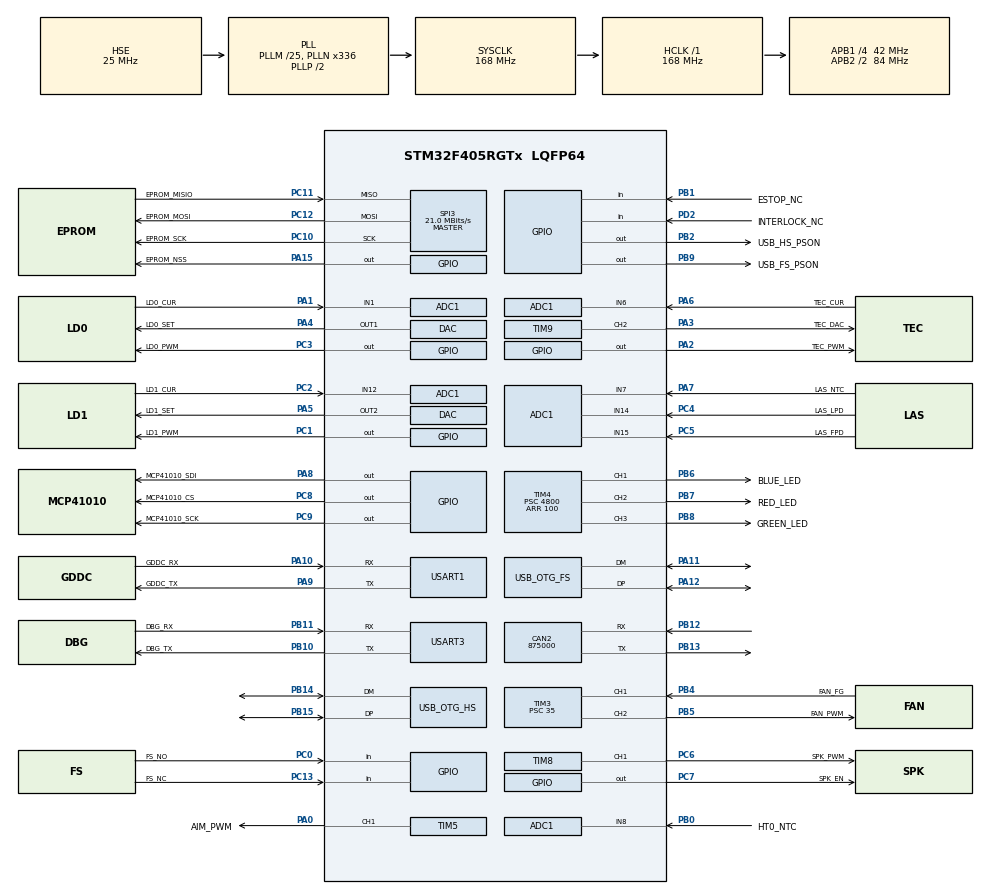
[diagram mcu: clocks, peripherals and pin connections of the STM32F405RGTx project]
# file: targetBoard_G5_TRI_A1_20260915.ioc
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ADC1.Channel-0\#ChannelRegularConversion=ADC_CHANNEL_1
ADC1.Channel-1\#ChannelRegularConversion=ADC_CHANNEL_6
ADC1.Channel-2\#ChannelRegularConversion=ADC_CHANNEL_7
ADC1.Channel-3\#ChannelRegularConversion=ADC_CHANNEL_8
ADC1.Channel-4\#ChannelRegularConversion=ADC_CHANNEL_12
ADC1.Channel-5\#ChannelRegularConversion=ADC_CHANNEL_14
ADC1.Channel-6\#ChannelRegularConversion=ADC_CHANNEL_15
ADC1.Channel-7\#ChannelRegularConversion=ADC_CHANNEL_TEMPSENSOR
ADC1.Channel-8\#ChannelRegularConversion=ADC_CHANNEL_VREFINT
ADC1.Channel-9\#ChannelRegularConversion=ADC_CHANNEL_VBAT
ADC1.ContinuousConvMode=ENABLE
ADC1.DMAContinuousRequests=ENABLE
ADC1.NbrOfConversion=10
ADC1.NbrOfConversionFlag=1
ADC1.Rank-0\#ChannelRegularConversion=1
ADC1.Rank-1\#ChannelRegularConversion=2
ADC1.Rank-2\#ChannelRegularConversion=3
ADC1.Rank-3\#ChannelRegularConversion=4
ADC1.Rank-4\#ChannelRegularConversion=5
ADC1.Rank-5\#ChannelRegularConversion=6
ADC1.Rank-6\#ChannelRegularConversion=7
ADC1.Rank-7\#ChannelRegularConversion=8
ADC1.Rank-8\#ChannelRegularConversion=9
ADC1.Rank-9\#ChannelRegularConversion=10
ADC1.SamplingTime-0\#ChannelRegularConversion=ADC_SAMPLETIME_144CYCLES
ADC1.SamplingTime-1\#ChannelRegularConversion=ADC_SAMPLETIME_144CYCLES
ADC1.SamplingTime-2\#ChannelRegularConversion=ADC_SAMPLETIME_144CYCLES
ADC1.SamplingTime-3\#ChannelRegularConversion=ADC_SAMPLETIME_144CYCLES
ADC1.SamplingTime-4\#ChannelRegularConversion=ADC_SAMPLETIME_144CYCLES
ADC1.SamplingTime-5\#ChannelRegularConversion=ADC_SAMPLETIME_144CYCLES
ADC1.SamplingTime-6\#ChannelRegularConversion=ADC_SAMPLETIME_144CYCLES
ADC1.SamplingTime-7\#ChannelRegularConversion=ADC_SAMPLETIME_144CYCLES
ADC1.SamplingTime-8\#ChannelRegularConversion=ADC_SAMPLETIME_144CYCLES
ADC1.SamplingTime-9\#ChannelRegularConversion=ADC_SAMPLETIME_144CYCLES
ADC1.ScanConvMode=ENABLE
ADC1.master=1
CAN2.CalculateBaudRate=875000
CAN2.CalculateTimeBit=1142
CAN2.CalculateTimeQuantum=380.95238095238096
Dma.ADC1.0.Direction=DMA_PERIPH_TO_MEMORY
Dma.ADC1.0.FIFOMode=DMA_FIFOMODE_ENABLE
Dma.ADC1.0.FIFOThreshold=DMA_FIFO_THRESHOLD_FULL
Dma.ADC1.0.Instance=DMA2_Stream0
Dma.ADC1.0.MemBurst=DMA_MBURST_SINGLE
Dma.ADC1.0.MemDataAlignment=DMA_MDATAALIGN_HALFWORD
Dma.ADC1.0.MemInc=DMA_MINC_ENABLE
Dma.ADC1.0.Mode=DMA_NORMAL
Dma.ADC1.0.PeriphBurst=DMA_PBURST_SINGLE
Dma.ADC1.0.PeriphDataAlignment=DMA_PDATAALIGN_HALFWORD
Dma.ADC1.0.PeriphInc=DMA_PINC_DISABLE
Dma.ADC1.0.Priority=DMA_PRIORITY_LOW
Dma.Request0=ADC1
FATFS._CODE_PAGE=437
FATFS._FS_EXFAT=1
FATFS._FS_LOCK=255
FATFS._STRF_ENCODE=0
FATFS._USE_CHMOD=1
FATFS._USE_EXPAND=1
FATFS._USE_FIND=1
FATFS._USE_FORWARD=1
FATFS._USE_LABEL=1
FATFS._USE_LFN=2
FATFS._USE_MUTEX=1
FATFS._USE_TRIM=1
FREERTOS.Mutexes01=xFatfsMutex,Static,myMutex02ControlBlock,Available
FREERTOS.RecursiveMutexes01=myRecursiveMutex01,Dynamic,NULL,Available
FREERTOS.Tasks01=defaultTask,24,512,StartDefaultTask,Default,NULL,Dynamic,NULL,NULL;mainAppTask,24,6144,StartMainAppTask,As external,NULL,Dynamic,NULL,NULL;cliTask,8,2048,StartCliTask,As external,NULL,Dynamic,NULL,NULL
FREERTOS.configENABLE_FPU=1
FREERTOS.configMINIMAL_STACK_SIZE=512
FREERTOS.configTOTAL_HEAP_SIZE=40960
FREERTOS.configUSE_APPLICATION_TASK_TAG=1
FREERTOS.configUSE_STATS_FORMATTING_FUNCTIONS=1
Mcu.Family=STM32F4
Mcu.Name=STM32F405RGTx
Mcu.Package=LQFP64
NVIC.ADC_IRQn=true\:5\:0\:false\:false\:true\:true\:true\:true\:true
NVIC.DMA2_Stream0_IRQn=true\:5\:0\:false\:false\:true\:true\:false\:true\:true
NVIC.OTG_FS_IRQn=true\:5\:0\:false\:false\:true\:true\:false\:true\:true
NVIC.OTG_HS_IRQn=true\:5\:0\:false\:false\:true\:true\:false\:true\:true
NVIC.PriorityGroup=NVIC_PRIORITYGROUP_4
NVIC.TIM7_IRQn=true\:5\:0\:false\:false\:true\:true\:true\:true\:true
NVIC.TIM8_TRG_COM_TIM14_IRQn=true\:5\:0\:false\:false\:true\:true\:true\:true\:true
NVIC.TIM8_UP_TIM13_IRQn=true\:15\:0\:false\:false\:true\:false\:false\:true\:true
NVIC.TimeBase=TIM8_UP_TIM13_IRQn
NVIC.TimeBaseIP=TIM13
NVIC.USART1_IRQn=true\:5\:0\:false\:false\:true\:true\:true\:true\:true
PA0-WKUP.GPIO_Label=AIM_PWM
PA0-WKUP.GPIO_PuPd=GPIO_PULLDOWN
PA0-WKUP.GPIO_Speed=GPIO_SPEED_FREQ_LOW
PA0-WKUP.Signal=S_TIM5_CH1
PA1.GPIO_Label=LD0_CUR
PA1.Signal=ADCx_IN1
PA10.GPIO_Label=GDDC_RX
PA10.GPIO_PuPd=GPIO_PULLDOWN
PA10.GPIO_Speed=GPIO_SPEED_FREQ_MEDIUM
PA10.Mode=Asynchronous
PA10.Signal=USART1_RX
PA11.Mode=Host_Only
PA11.Signal=USB_OTG_FS_DM
PA12.Mode=Host_Only
PA12.Signal=USB_OTG_FS_DP
PA13.Mode=Trace_Asynchronous_SW
PA13.Signal=SYS_JTMS-SWDIO
PA14.Mode=Trace_Asynchronous_SW
PA14.Signal=SYS_JTCK-SWCLK
PA15.GPIO_Label=EPROM_NSS
PA15.GPIO_PuPd=GPIO_PULLUP
PA15.GPIO_Speed=GPIO_SPEED_FREQ_VERY_HIGH
PA15.Signal=GPIO_Output
PA2.GPIO_Label=TEC_PWM
PA2.GPIO_PuPd=GPIO_PULLDOWN
PA2.Signal=GPIO_Output
PA3.GPIO_Label=TEC_DAC
PA3.GPIO_PuPd=GPIO_PULLDOWN
PA3.GPIO_Speed=GPIO_SPEED_FREQ_LOW
PA3.Signal=S_TIM9_CH2
PA4.GPIO_Label=LD0_SET
PA4.Signal=COMP_DAC1_group
PA5.GPIO_Label=LD1_SET
PA5.Signal=COMP_DAC2_group
PA6.GPIO_Label=TEC_CUR
PA6.Signal=ADCx_IN6
PA7.GPIO_Label=LAS_NTC
PA7.Signal=ADCx_IN7
PA8.GPIO_Label=MCP41010_SDI
PA8.GPIO_PuPd=GPIO_PULLDOWN
PA8.GPIO_Speed=GPIO_SPEED_FREQ_VERY_HIGH
PA8.Signal=GPIO_Output
PA9.GPIO_Label=GDDC_TX
PA9.GPIO_PuPd=GPIO_PULLDOWN
PA9.GPIO_Speed=GPIO_SPEED_FREQ_MEDIUM
PA9.Mode=Asynchronous
PA9.Signal=USART1_TX
PB0.GPIO_Label=HT0_NTC
PB0.Signal=ADCx_IN8
PB1.GPIO_Label=ESTOP_NC
PB1.Signal=GPIO_Input
PB10.GPIO_Label=DBG_TX
PB10.GPIO_PuPd=GPIO_PULLDOWN
PB10.GPIO_Speed=GPIO_SPEED_FREQ_MEDIUM
PB10.Mode=Asynchronous
PB10.Signal=USART3_TX
PB11.GPIO_Label=DBG_RX
PB11.GPIO_PuPd=GPIO_PULLDOWN
PB11.GPIO_Speed=GPIO_SPEED_FREQ_MEDIUM
PB11.Mode=Asynchronous
PB11.Signal=USART3_RX
PB12.Mode=CAN_Activate
PB12.Signal=CAN2_RX
PB13.Mode=CAN_Activate
PB13.Signal=CAN2_TX
PB14.Mode=Host_FS
PB14.Signal=USB_OTG_HS_DM
PB15.Mode=Host_FS
PB15.Signal=USB_OTG_HS_DP
PB2.GPIO_Label=USB_HS_PSON
PB2.GPIO_PuPd=GPIO_PULLDOWN
PB2.Signal=GPIO_Output
PB3.Mode=Trace_Asynchronous_SW
PB3.Signal=SYS_JTDO-SWO
PB4.GPIO_Label=FAN_FG
PB4.Signal=S_TIM3_CH1
PB5.GPIO_Label=FAN_PWM
PB5.Signal=S_TIM3_CH2
PB6.GPIO_Label=BLUE_LED
PB6.GPIO_PuPd=GPIO_PULLDOWN
PB6.Signal=S_TIM4_CH1
PB7.GPIO_Label=RED_LED
PB7.GPIO_PuPd=GPIO_PULLDOWN
PB7.Signal=S_TIM4_CH2
PB8.GPIO_Label=GREEN_LED
PB8.GPIO_PuPd=GPIO_PULLDOWN
PB8.Signal=S_TIM4_CH3
PB9.GPIO_Label=USB_FS_PSON
PB9.GPIO_PuPd=GPIO_PULLDOWN
PB9.Signal=GPIO_Output
PC0.GPIO_Label=FS_NO
PC0.Signal=GPIO_Input
PC1.GPIO_Label=LD1_PWM
PC1.GPIO_PuPd=GPIO_PULLDOWN
PC1.Signal=GPIO_Output
PC10.GPIO_Label=EPROM_SCK
PC10.GPIO_PuPd=GPIO_PULLDOWN
PC10.Mode=Full_Duplex_Master
PC10.Signal=SPI3_SCK
PC11.GPIO_Label=EPROM_MISIO
PC11.GPIO_PuPd=GPIO_PULLDOWN
PC11.Mode=Full_Duplex_Master
PC11.Signal=SPI3_MISO
PC12.GPIO_Label=EPROM_MOSI
PC12.GPIO_PuPd=GPIO_PULLDOWN
PC12.Mode=Full_Duplex_Master
PC12.Signal=SPI3_MOSI
PC13-ANTI_TAMP.GPIO_Label=FS_NC
PC13-ANTI_TAMP.Signal=GPIO_Input
PC14-OSC32_IN.Signal=RCC_OSC32_IN
PC15-OSC32_OUT.Signal=RCC_OSC32_OUT
PC2.GPIO_Label=LD1_CUR
PC2.Signal=ADCx_IN12
PC3.GPIO_Label=LD0_PWM
PC3.GPIO_PuPd=GPIO_PULLDOWN
PC3.Signal=GPIO_Output
PC4.GPIO_Label=LAS_LPD
PC4.Signal=ADCx_IN14
PC5.GPIO_Label=LAS_FPD
PC5.Signal=ADCx_IN15
PC6.GPIO_Label=SPK_PWM
PC6.GPIO_PuPd=GPIO_PULLDOWN
PC6.Signal=S_TIM8_CH1
PC7.GPIO_Label=SPK_EN
PC7.GPIO_PuPd=GPIO_PULLDOWN
PC7.Signal=GPIO_Output
PC8.GPIO_Label=MCP41010_CS
PC8.GPIO_PuPd=GPIO_PULLUP
PC8.GPIO_Speed=GPIO_SPEED_FREQ_VERY_HIGH
PC8.Signal=GPIO_Output
PC9.GPIO_Label=MCP41010_SCK
PC9.GPIO_PuPd=GPIO_PULLDOWN
PC9.GPIO_Speed=GPIO_SPEED_FREQ_VERY_HIGH
PC9.Signal=GPIO_Output
PD2.GPIO_Label=INTERLOCK_NC
PD2.Signal=GPIO_Input
PH0-OSC_IN.Mode=HSE-External-Oscillator
PH0-OSC_IN.Signal=RCC_OSC_IN
PH1-OSC_OUT.Mode=HSE-External-Oscillator
PH1-OSC_OUT.Signal=RCC_OSC_OUT
ProjectManager.HeapSize=0x1000
ProjectManager.StackSize=0x1800
ProjectManager.TargetToolchain=MDK-ARM V5.32
RCC.48MHZClocksFreq_Value=48000000
RCC.AHBFreq_Value=168000000
RCC.APB1CLKDivider=RCC_HCLK_DIV4
RCC.APB1Freq_Value=42000000
RCC.APB1TimFreq_Value=84000000
RCC.APB2CLKDivider=RCC_HCLK_DIV2
RCC.APB2Freq_Value=84000000
RCC.APB2TimFreq_Value=168000000
RCC.CortexFreq_Value=168000000
RCC.HCLKFreq_Value=168000000
RCC.HSE_VALUE=25000000
RCC.HSI_VALUE=16000000
RCC.PLLM=25
RCC.PLLN=336
RCC.PLLQ=7
RCC.RCC_RTC_Clock_Source=RCC_RTCCLKSOURCE_LSI
RCC.RCC_RTC_Clock_SourceVirtual=RCC_RTCCLKSOURCE_LSE
RCC.RCC_RTC_Clock_Source_FROM_HSE=RCC_RTCCLKSOURCE_HSE_DIV25
RCC.SYSCLKFreq_VALUE=168000000
RCC.SYSCLKSource=RCC_SYSCLKSOURCE_PLLCLK
RCC.VCOOutputFreq_Value=336000000
RTC.Format=RTC_FORMAT_BCD
SH.ADCx_IN1.0=ADC1_IN1,IN1
SH.ADCx_IN12.0=ADC1_IN12,IN12
SH.ADCx_IN14.0=ADC1_IN14,IN14
SH.ADCx_IN15.0=ADC1_IN15,IN15
SH.ADCx_IN6.0=ADC1_IN6,IN6
SH.ADCx_IN7.0=ADC1_IN7,IN7
SH.ADCx_IN8.0=ADC1_IN8,IN8
SH.COMP_DAC1_group.0=DAC_OUT1,DAC_OUT1
SH.COMP_DAC2_group.0=DAC_OUT2,DAC_OUT2
SH.S_TIM3_CH1.0=TIM3_CH1,Input_Capture1_from_TI1
SH.S_TIM3_CH2.0=TIM3_CH2,PWM Generation2 CH2
SH.S_TIM4_CH1.0=TIM4_CH1,PWM Generation1 CH1
SH.S_TIM4_CH2.0=TIM4_CH2,PWM Generation2 CH2
SH.S_TIM4_CH3.0=TIM4_CH3,PWM Generation3 CH3
SH.S_TIM5_CH1.0=TIM5_CH1,PWM Generation1 CH1
SH.S_TIM8_CH1.0=TIM8_CH1,PWM Generation1 CH1
SH.S_TIM9_CH2.0=TIM9_CH2,PWM Generation2 CH2
SPI3.CalculateBaudRate=21.0 MBits/s
SPI3.Direction=SPI_DIRECTION_2LINES
SPI3.Mode=SPI_MODE_MASTER
SPI3.VirtualType=VM_MASTER
TIM14.AutoReloadPreload=TIM_AUTORELOAD_PRELOAD_ENABLE
TIM14.Period=1000
TIM14.Prescaler=84
TIM3.AutoReloadPreload=TIM_AUTORELOAD_PRELOAD_ENABLE
TIM3.Channel-Input_Capture1_from_TI1=TIM_CHANNEL_1
TIM3.Channel-PWM\ Generation2\ CH2=TIM_CHANNEL_2
TIM3.Period=100
TIM3.Prescaler=35
TIM4.AutoReloadPreload=TIM_AUTORELOAD_PRELOAD_ENABLE
TIM4.Channel-PWM\ Generation1\ CH1=TIM_CHANNEL_1
TIM4.Channel-PWM\ Generation2\ CH2=TIM_CHANNEL_2
TIM4.Channel-PWM\ Generation3\ CH3=TIM_CHANNEL_3
TIM4.Period=100
TIM4.Prescaler=4800
TIM5.AutoReloadPreload=TIM_AUTORELOAD_PRELOAD_ENABLE
TIM5.Channel-PWM\ Generation1\ CH1=TIM_CHANNEL_1
TIM5.Period=5000
TIM5.Prescaler=96
TIM7.AutoReloadPreload=TIM_AUTORELOAD_PRELOAD_ENABLE
TIM7.Period=1000
TIM7.Prescaler=84
TIM7.TIM_MasterOutputTrigger=TIM_TRGO_RESET
TIM8.AutoReloadPreload=TIM_AUTORELOAD_PRELOAD_ENABLE
TIM8.Channel-PWM\ Generation1\ CH1=TIM_CHANNEL_1
TIM8.Period=100
TIM8.Prescaler=35
TIM9.AutoReloadPreload=TIM_AUTORELOAD_PRELOAD_ENABLE
TIM9.Channel-PWM\ Generation2\ CH2=TIM_CHANNEL_2
TIM9.Period=4095
USART1.VirtualMode=VM_ASYNC
USART3.VirtualMode=VM_ASYNC
USB_HOST.BSP.number=2
USB_HOST.USBH_DEBUG_LEVEL-ALL_Classes_HS=3
USB_HOST.USBH_HandleTypeDef-ALL_Classes_FS=hUsbHostFS
USB_HOST.USBH_HandleTypeDef-ALL_Classes_HS=hUsbHostHS
USB_HOST.USBH_MAX_DATA_BUFFER-ALL_Classes_HS=1024
USB_HOST.VirtualModeFS=All_Classes
USB_HOST.VirtualModeHS=All_Classes
USB_HOST0.BSP.STBoard=false
USB_HOST0.BSP.api=Unknown
USB_HOST0.BSP.condition=ALL_SW_VBUS_DRIVE_FS \= false
USB_HOST0.BSP.instance=PB9
USB_HOST0.BSP.ip=GPIO
USB_HOST0.BSP.mode=Output
USB_HOST0.BSP.name=Drive_VBUS_FS
USB_HOST0.BSP.solution=PB9
USB_HOST1.BSP.STBoard=false
USB_HOST1.BSP.api=Unknown
USB_HOST1.BSP.condition=ALL_SW_VBUS_DRIVE_HS \= false
USB_HOST1.BSP.instance=PB2
USB_HOST1.BSP.ip=GPIO
USB_HOST1.BSP.mode=Output
USB_HOST1.BSP.name=Drive_VBUS_HS
USB_HOST1.BSP.solution=PB2
USB_OTG_FS.VirtualMode=Host_Only
USB_OTG_FS.phy_itface=HCD_PHY_EMBEDDED
USB_OTG_HS.VirtualMode-Host_FS=Host_FS
USB_OTG_HS.dma_enable-Host_FS=ENABLE
VP_ADC1_TempSens_Input.Mode=IN-TempSens
VP_ADC1_Vbat_Input.Mode=IN-Vbat
VP_ADC1_Vref_Input.Mode=IN-Vrefint
VP_FATFS_VS_USB.Mode=USB
VP_FREERTOS_VS_CMSIS_V2.Mode=CMSIS_V2
VP_LIBJPEG_VS_JPEGLIB.Mode=Enabled
VP_MBEDTLS_VS_MBEDTLS.Mode=Enabled
VP_RNG_VS_RNG.Mode=RNG_Activate
VP_RTC_VS_RTC_Activate.Mode=RTC_Enabled
VP_RTC_VS_RTC_Calendar.Mode=RTC_Calendar
VP_SYS_VS_tim13.Mode=TIM13
VP_TIM14_VS_ClockSourceINT.Mode=Enable_Timer
VP_TIM3_VS_ClockSourceINT.Mode=Internal
VP_TIM4_VS_ClockSourceINT.Mode=Internal
VP_TIM5_VS_ClockSourceINT.Mode=Internal
VP_TIM7_VS_ClockSourceINT.Mode=Enable_Timer
VP_TIM8_VS_ClockSourceINT.Mode=Internal
VP_TIM9_VS_ClockSourceINT.Mode=Internal
VP_USB_HOST_VS_USB_HOST_ALL_CLASS_FS.Mode=ALL_Classes_FS
VP_USB_HOST_VS_USB_HOST_ALL_CLASS_HS.Mode=ALL_Classes_HS
board=custom

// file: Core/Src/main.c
/* USER CODE BEGIN Header */
/**
  ******************************************************************************
  * @file           : main.c
  * @brief          : Main program body
  ******************************************************************************
  * @attention
  *
  * Copyright (c) 2026 STMicroelectronics.
  * All rights reserved.
  *
  * This software is licensed under terms that can be found in the LICENSE file
  * in the root directory of this software component.
  * If no LICENSE file comes with this software, it is provided AS-IS.
  *
  ******************************************************************************
  */
/*----------------------------------------------------------------------------
 * 文件编码约定: 本文件为 UTF-8 编码(带BOM)。
 * 本工程源码统一使用 UTF-8(带BOM) 保存: 新建或修改任何源文件时,
 * 请以 UTF-8 编码保存, 并在文件头保留本注释;
 * 若保存成无BOM的 UTF-8, Keil 会按 GBK 解码, 中文注释将显示为乱码。
 * 本注释位于 USER CODE Header 区, CubeMX 重新生成代码时会保留。
 *----------------------------------------------------------------------------*/
/* USER CODE END Header */
#include "main.h"
#include "cmsis_os.h"
#include "adc.h"
#include "can.h"
#include "dac.h"
#include "dma.h"
#include "fatfs.h"
#include "libjpeg.h"
#include "mbedtls.h"
#include "rng.h"
#include "rtc.h"
#include "spi.h"
#include "tim.h"
#include "usart.h"
#include "usb_host.h"
#include "gpio.h"

/* USER CODE BEGIN Includes */
#include "sPlc.h"
extern void sPlcTimerIsr(void);
extern void sPlcLaserTimerIsr(void);

/* USER CODE END Includes */

/* USER CODE BEGIN PV */
//* 全局FATFS变量在main.c中定义 */
//SemaphoreHandle_t xFatfsMutex = NULL;

/* USER CODE END PV */

void SystemClock_Config(void);
void MX_FREERTOS_Init(void);

int main(void)
{

  /* MCU Configuration--------------------------------------------------------*/

  /* Reset of all peripherals, Initializes the Flash interface and the Systick. */
  HAL_Init();

  /* Configure the system clock */
  SystemClock_Config();

  /* Initialize all configured peripherals */
  MX_GPIO_Init();
  MX_DMA_Init();
  MX_ADC1_Init();
  MX_CAN2_Init();
  MX_DAC_Init();
  MX_SPI3_Init();
  MX_TIM3_Init();
  MX_TIM5_Init();
  MX_TIM8_Init();
  MX_TIM9_Init();
  MX_USART1_UART_Init();
  MX_USART3_UART_Init();
  MX_TIM4_Init();
  MX_RNG_Init();
  MX_FATFS_Init();
  MX_LIBJPEG_Init();
  MX_TIM7_Init();
  MX_TIM14_Init();
  MX_RTC_Init();
  /* Call PreOsInit function */
  MX_MBEDTLS_Init();

  /* Init scheduler */
  osKernelInitialize();  /* Call init function for freertos objects (in cmsis_os2.c) */
  MX_FREERTOS_Init();

  /* Start scheduler */
  osKernelStart();

  /* We should never get here as control is now taken by the scheduler */

  /* Infinite loop */
  while (1)
  {

  }
}

void SystemClock_Config(void)
{
  RCC_OscInitTypeDef RCC_OscInitStruct = {0};
  RCC_ClkInitTypeDef RCC_ClkInitStruct = {0};

  /** Configure the main internal regulator output voltage
  */
  __HAL_RCC_PWR_CLK_ENABLE();
  __HAL_PWR_VOLTAGESCALING_CONFIG(PWR_REGULATOR_VOLTAGE_SCALE1);

  /** Initializes the RCC Oscillators according to the specified parameters
  * in the RCC_OscInitTypeDef structure.
  */
  RCC_OscInitStruct.OscillatorType = RCC_OSCILLATORTYPE_LSI|RCC_OSCILLATORTYPE_HSE;
  RCC_OscInitStruct.HSEState = RCC_HSE_ON;
  RCC_OscInitStruct.LSIState = RCC_LSI_ON;
  RCC_OscInitStruct.PLL.PLLState = RCC_PLL_ON;
  RCC_OscInitStruct.PLL.PLLSource = RCC_PLLSOURCE_HSE;
  RCC_OscInitStruct.PLL.PLLM = 25;
  RCC_OscInitStruct.PLL.PLLN = 336;
  RCC_OscInitStruct.PLL.PLLP = RCC_PLLP_DIV2;
  RCC_OscInitStruct.PLL.PLLQ = 7;
  if (HAL_RCC_OscConfig(&RCC_OscInitStruct) != HAL_OK)
  {
    Error_Handler();
  }

  /** Initializes the CPU, AHB and APB buses clocks
  */
  RCC_ClkInitStruct.ClockType = RCC_CLOCKTYPE_HCLK|RCC_CLOCKTYPE_SYSCLK
                              |RCC_CLOCKTYPE_PCLK1|RCC_CLOCKTYPE_PCLK2;
  RCC_ClkInitStruct.SYSCLKSource = RCC_SYSCLKSOURCE_PLLCLK;
  RCC_ClkInitStruct.AHBCLKDivider = RCC_SYSCLK_DIV1;
  RCC_ClkInitStruct.APB1CLKDivider = RCC_HCLK_DIV4;
  RCC_ClkInitStruct.APB2CLKDivider = RCC_HCLK_DIV2;

  if (HAL_RCC_ClockConfig(&RCC_ClkInitStruct, FLASH_LATENCY_5) != HAL_OK)
  {
    Error_Handler();
  }
}

void HAL_TIM_PeriodElapsedCallback(TIM_HandleTypeDef *htim)
{
  if (htim->Instance == TIM13)
  {
    HAL_IncTick();
  }
  /* USER CODE BEGIN Callback 1 */
	if(htim->Instance == CONFIG_SPLC_TIM) {
		sPlcTimerIsr();
	}
	if(htim->Instance == CONFIG_LASER_TIM){
		sPlcLaserTimerIsr();
	}

  /* USER CODE END Callback 1 */
}

void Error_Handler(void)
{
  __disable_irq();
  while (1)
  {
  }
}

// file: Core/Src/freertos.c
/* USER CODE BEGIN Header */
/**
  ******************************************************************************
  * File Name          : freertos.c
  * Description        : Code for freertos applications
  ******************************************************************************
  * @attention
  *
  * Copyright (c) 2026 STMicroelectronics.
  * All rights reserved.
  *
  * This software is licensed under terms that can be found in the LICENSE file
  * in the root directory of this software component.
  * If no LICENSE file comes with this software, it is provided AS-IS.
  *
  ******************************************************************************
  */
/*----------------------------------------------------------------------------
 * 文件编码约定: 本文件为 UTF-8 编码(带BOM)。
 * 本工程源码统一使用 UTF-8(带BOM) 保存: 新建或修改任何源文件时,
 * 请以 UTF-8 编码保存, 并在文件头保留本注释;
 * 若保存成无BOM的 UTF-8, Keil 会按 GBK 解码, 中文注释将显示为乱码。
 * 本注释位于 USER CODE Header 区, CubeMX 重新生成代码时会保留。
 *----------------------------------------------------------------------------*/
/* USER CODE END Header */

#include "FreeRTOS.h"
#include "task.h"
#include "main.h"
#include "cmsis_os.h"

typedef StaticSemaphore_t osStaticMutexDef_t;

/* Definitions for defaultTask */
osThreadId_t defaultTaskHandle;
const osThreadAttr_t defaultTask_attributes = {
  .name = "defaultTask",
  .stack_size = 512 * 4,
  .priority = (osPriority_t) osPriorityNormal,
};
/* Definitions for mainAppTask */
osThreadId_t mainAppTaskHandle;
const osThreadAttr_t mainAppTask_attributes = {
  .name = "mainAppTask",
  .stack_size = 6144 * 4,
  .priority = (osPriority_t) osPriorityNormal,
};
/* Definitions for cliTask */
osThreadId_t cliTaskHandle;
const osThreadAttr_t cliTask_attributes = {
  .name = "cliTask",
  .stack_size = 2048 * 4,
  .priority = (osPriority_t) osPriorityLow,
};
/* Definitions for xFatfsMutex */
osMutexId_t xFatfsMutexHandle;
osStaticMutexDef_t myMutex02ControlBlock;
const osMutexAttr_t xFatfsMutex_attributes = {
  .name = "xFatfsMutex",
  .cb_mem = &myMutex02ControlBlock,
  .cb_size = sizeof(myMutex02ControlBlock),
};
/* Definitions for myRecursiveMutex01 */
osMutexId_t myRecursiveMutex01Handle;
const osMutexAttr_t myRecursiveMutex01_attributes = {
  .name = "myRecursiveMutex01",
  .attr_bits = osMutexRecursive,
};

void StartDefaultTask(void *argument);
extern void StartMainAppTask(void *argument);
extern void StartCliTask(void *argument);

extern void MX_USB_HOST_Init(void);
void MX_FREERTOS_Init(void); /* (MISRA C 2004 rule 8.1) */

void MX_FREERTOS_Init(void) {
  /* Create the mutex(es) */
  /* creation of xFatfsMutex */
  xFatfsMutexHandle = osMutexNew(&xFatfsMutex_attributes);

  /* Create the recursive mutex(es) */
  /* creation of myRecursiveMutex01 */
  myRecursiveMutex01Handle = osMutexNew(&myRecursiveMutex01_attributes);

  /* USER CODE BEGIN RTOS_MUTEX */
	/* 互斥量初始化 */
    //xFatfsMutex = xSemaphoreCreateMutex();
  /* add mutexes, ... */
  /* USER CODE END RTOS_MUTEX */

  /* Create the thread(s) */
  /* creation of defaultTask */
  defaultTaskHandle = osThreadNew(StartDefaultTask, NULL, &defaultTask_attributes);

  /* creation of mainAppTask */
  mainAppTaskHandle = osThreadNew(StartMainAppTask, NULL, &mainAppTask_attributes);

  /* creation of cliTask */
  cliTaskHandle = osThreadNew(StartCliTask, NULL, &cliTask_attributes);

}

void StartDefaultTask(void *argument)
{
  /* init code for USB_HOST */
  MX_USB_HOST_Init();
  for(;;)
  {
    osDelay(1);
  }
}
